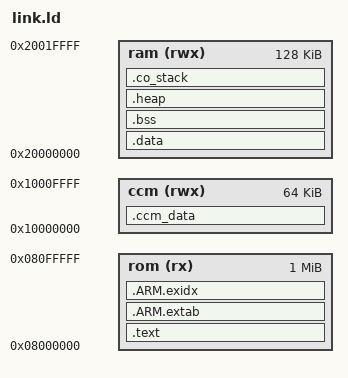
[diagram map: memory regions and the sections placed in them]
OUTPUT_FORMAT ("elf32-littlearm", "elf32-bigarm", "elf32-littlearm")
SEARCH_DIR(.)

MEMORY
{
	rom (rx)  : ORIGIN = 0x08000000, LENGTH = 1024K
	ram (rwx) : ORIGIN = 0x20000000, LENGTH = 128K
	ccm (rwx) : ORIGIN = 0x10000000, LENGTH = 64K /* core coupled memory */
}
/* Library configurations */
GROUP(libgcc.a libc.a libm.a libnosys.a)

_eram = 0x20000000 + 0x00020000;

/* Section Definitions */ 
SECTIONS 
{ 
    .text : 
    { 
        KEEP(*(.isr_vector .isr_vector.*)) 
        *(.text .text.* .gnu.linkonce.t.*) 	      
        *(.glue_7t) *(.glue_7)		                
        *(.rodata .rodata* .gnu.linkonce.r.*)		    	                  
    } > rom
    
    .ARM.extab : 
    {
        *(.ARM.extab* .gnu.linkonce.armextab.*)
    } > rom
    
    .ARM.exidx :
    {
        *(.ARM.exidx* .gnu.linkonce.armexidx.*)
    } > rom
    
    . = ALIGN(4); 
    _etext = .;
    _sidata = .; 
    		
    .data : AT (_etext) 
    { 
        _sdata = .; 
        *(.data .data.*) 
        . = ALIGN(4); 
        _edata = . ;
    } > ram

    /* .bss section which is used for uninitialized data */ 
    .bss (NOLOAD) : 
    { 
        _sbss = . ; 
        *(.bss .bss.*) 
        *(COMMON) 
        . = ALIGN(4); 
        _ebss = . ; 
    } > ram
    
    .heap :
	{
		__end__ = .;
		end = __end__;
		*(.heap*)
		__HeapLimit = .;
	} > ram
	
    /* stack section */
    .co_stack (NOLOAD):
    {
        . = ALIGN(8);
        *(.co_stack .co_stack.*)
    } > ram
	
	/* CCM section, vars must be located here explicitly */
  /* Example: int foo __attribute__ ((section (".ccmdata"))); */
  .ccm_data :
  {
    *(.ccmdata)
    *(.ccmdata*)
  } > ccm
       
    . = ALIGN(4); 
    _end = . ; 
} 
